AUTOSAR XML (schema 4-0-3)
package /ServiceSwComponent_FiM/PortInterface
  client server interface FunctionInhibition: is-service=true, service-kind=FUNCTION-INHIBITION-MANAGER
    operation GetFunctionPermission: possible-error=E_NOT_OK
      arg Permission: type=boolean, direction=OUT
    error E_NOT_OK: error-code=1
package /ServiceSwComponent_FiM/ImplementationDataType
  impl type FiM_FunctionIdType: category=VALUE, base-type=uint8
package /ServiceSwComponent_FiM/SwComponentType
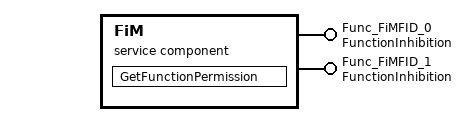
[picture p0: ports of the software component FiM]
  service sw component type FiM
    provide port Func_FiMFID_0: server-com-spec{operation=GetFunctionPermission, queue-length=1}, provided-interface=FunctionInhibition
    provide port Func_FiMFID_1: server-com-spec{operation=GetFunctionPermission, queue-length=1}, provided-interface=FunctionInhibition
    behavior InternalBehaviors_FiM
      exclusive area REQUEST_EVENTID_PROTECTION
      exclusive area REQUEST_FID_PROTECTION
      operation invoked event OIE_GetFunctionPermission_FiMFID_0: start-on-event=GetFunctionPermission, operation=Func_FiMFID_0.GetFunctionPermission
      operation invoked event OIE_GetFunctionPermission_FiMFID_1: start-on-event=GetFunctionPermission, operation=Func_FiMFID_1.GetFunctionPermission
      port-api-options:
        {enable-take-address=false, indirect-api=false, port-defined-argument-value{value=0, value-type=FiM_FunctionIdType}, port=Func_FiMFID_0}
        {enable-take-address=false, indirect-api=false, port-defined-argument-value{value=1, value-type=FiM_FunctionIdType}, port=Func_FiMFID_1}
      runnable GetFunctionPermission: can-enter-exclusive-area=[REQUEST_EVENTID_PROTECTION, REQUEST_FID_PROTECTION], can-be-invoked-concurrently=true, symbol=FiM_GetFunctionPermission
